# GD32H77x_78x register map
File version: 1.0
CPU: CM7 r1p2, little endian, MPU, FPU, 4 interrupt priority bits
Registers are 32-bit, read-write, reset 0x0 unless marked. A register's access mark holds for its fields unless they carry their own. Offsets are from the block's base; [hi:lo] are bit positions; {n}, {i} and the like mark numbered series.

## CAU — Cryptographic acceleration unit
Base 0x48021000
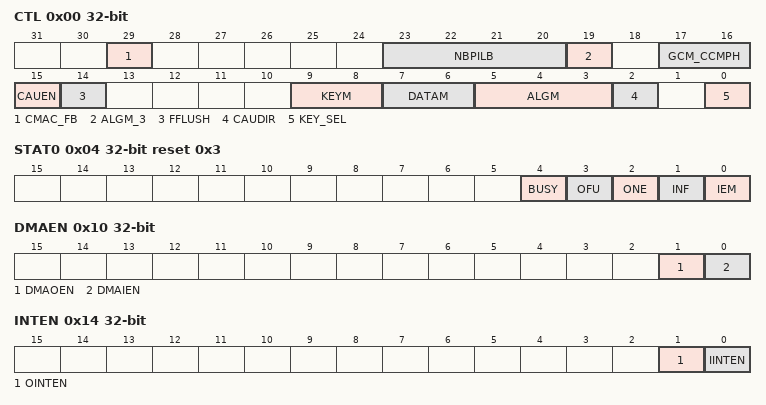
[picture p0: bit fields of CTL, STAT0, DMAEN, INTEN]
0x00 CTL access per field — CAU control register
  [29] CMAC_FB rw — CMAC generate mac final block control
  [23:20] NBPILB rw — Number of bytes padding in last block of payload
  [19] ALGM_3 rw — Encryption/decryption algorithm mode bit 3
  [17:16] GCM_CCMPH rw — GCM CCM phase
  [15] CAUEN rw — Cryptographic module enable
  [14] FFLUSH wo — FIFO flush
  [9:8] KEYM rw — AES key size mode configuration
  [7:6] DATAM rw — Data swapping type mode configuration
  [5:3] ALGM rw — Encryption/decryption algorithm mode
  [2] CAUDIR rw — CAU direction
  [0] KEY_SEL rw — Key select
0x04 STAT0 ro reset 0x3 — CAU status register 0
  [4] BUSY — BUSY flag
  [3] OFU — OUT FIFO full flag
  [2] ONE — OUT FIFO not empty flag
  [1] INF — IN FIFO not full flag
  [0] IEM — IN FIFO empty flag
0x08 DI — CAU data input register
  [31:0] DI — Data input
0x0C DO ro — CAU data output register
  [31:0] DO — Data output
0x10 DMAEN — CAU DMA enable register
  [1] DMAOEN — Out FIFO DMA enable
  [0] DMAIEN — In FIFO DMA enable
0x14 INTEN — CAU interrupt enable register
  [1] OINTEN — Out FIFO interrupt enable
  [0] IINTEN — In FIFO interrupt enable
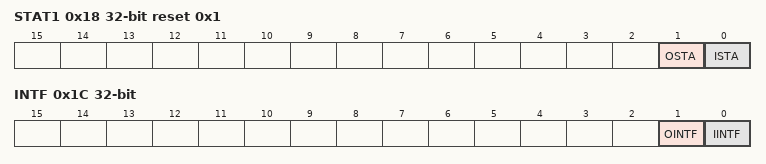
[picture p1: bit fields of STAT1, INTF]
0x18 STAT1 ro reset 0x1 — CAU interrupt status flag register 1
  [1] OSTA — Out FIFO interrupt flag
  [0] ISTA — In FIFO interrupt flag
0x1C INTF ro — CAU enable interrupt status flag register
  [1] OINTF — Out FIFO enabled interrupt flag
  [0] IINTF — In FIFO enabled interrupt flag
{0x20+8i} KEY{i}H wo (i=0..3) — CAU key register
  [31:0] KEY{i}H — Key for DES,TDES,AES
{0x24+8i} KEY{i}L wo (i=0..3) — CAU key register
  [31:0] KEY{i}L — Key for DES,TDES,AES
0x40 IV0H — CAU initialization register
  [31:0] IV0H — The initialization vector for DES,TDES,AES
0x44 IV0L — CAU initialization register
  [31:0] IV0L — The initialization vector for DES,TDES,AES
0x48 IV1H — CAU initialization register
  [31:0] IV1H — The initialization vector for DES,TDES,AES
0x4C IV1L — CAU initialization register
  [31:0] IV1L — The initialization vector for DES,TDES,AES
{0x50+4i} GCMCCMCTXS{i} (i=0..7) — GCM or CCM mode context switch register {i}
  [31:0] CTX{i} — The internal status of the CAU core
{0x70+4i} GCMCTXS{i} (i=0..7) — GCM mode context switch register {i}
  [31:0] CTX{i} — The internal status of the CAU core
{0x90+4i} CMACCTXS{i} (i=0..3) — CMAC mode context switch register {i}
  [31:0] CTX{i} — The internal status of the CAU core

## CMP — Comparator
Base 0x58003800
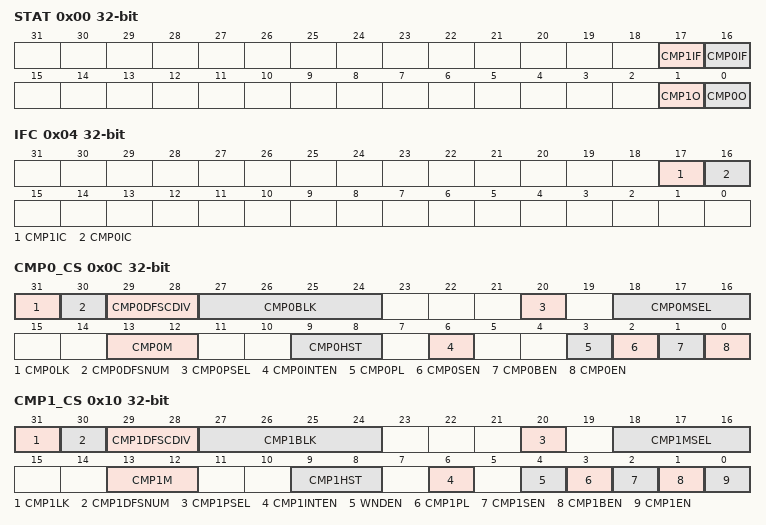
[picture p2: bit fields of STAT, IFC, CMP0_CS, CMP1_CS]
0x00 STAT access per field — Status register
  [17] CMP1IF rw — CMP1 interrupt flag
  [16] CMP0IF rw — CMP0 interrupt flag
  [1] CMP1O ro — CMP1 output
  [0] CMP0O ro — CMP0 output
0x04 IFC wo — Interrupt flag clear register
  [17] CMP1IC — CMP1 interrupt flag clear
  [16] CMP0IC — CMP0 interrupt flag clear
0x08 SR — Alternate select register
  [10:0] AFSE — CMP alternate function of output ports select
0x0C CMP0_CS — CMP0 Control/status register
  [31] CMP0LK — CMP0 lock
  [30] CMP0DFSNUM — CMP0 digital filter sampling number
  [29:28] CMP0DFSCDIV — CMP0 digital filter sampling clock division
  [27:24] CMP0BLK — CMP0 output blanking source
  [20] CMP0PSEL — CMP0_IP input selection
  [18:16] CMP0MSEL — CMP0_IM internal input selection
  [13:12] CMP0M — CMP0 mode
  [9:8] CMP0HST — CMP0 hysteresis
  [6] CMP0INTEN — CMP0 interrupt enable
  [3] CMP0PL — Polarity of CMP0 output
  [2] CMP0SEN — Voltage scaler enable bit
  [1] CMP0BEN — Scaler bridge enable bit
  [0] CMP0EN — CMP0 enable
0x10 CMP1_CS — CMP1 Control/status register
  [31] CMP1LK — CMP1 lock
  [30] CMP1DFSNUM — CMP1 digital filter sampling number
  [29:28] CMP1DFSCDIV — CMP1 digital filter sampling clock division
  [27:24] CMP1BLK — CMP1 output blanking source
  [20] CMP1PSEL — CMP1_IP input selection
  [18:16] CMP1MSEL — CMP1_IM internal input selection
  [13:12] CMP1M — CMP1 mode
  [9:8] CMP1HST — CMP1 hysteresis
  [6] CMP1INTEN — CMP1 interrupt enable
  [4] WNDEN — Window mode enable
  [3] CMP1PL — Polarity of CMP1 output
  [2] CMP1SEN — Voltage scaler enable bit
  [1] CMP1BEN — Scaler bridge enable bit
  [0] CMP1EN — CMP1 enable
